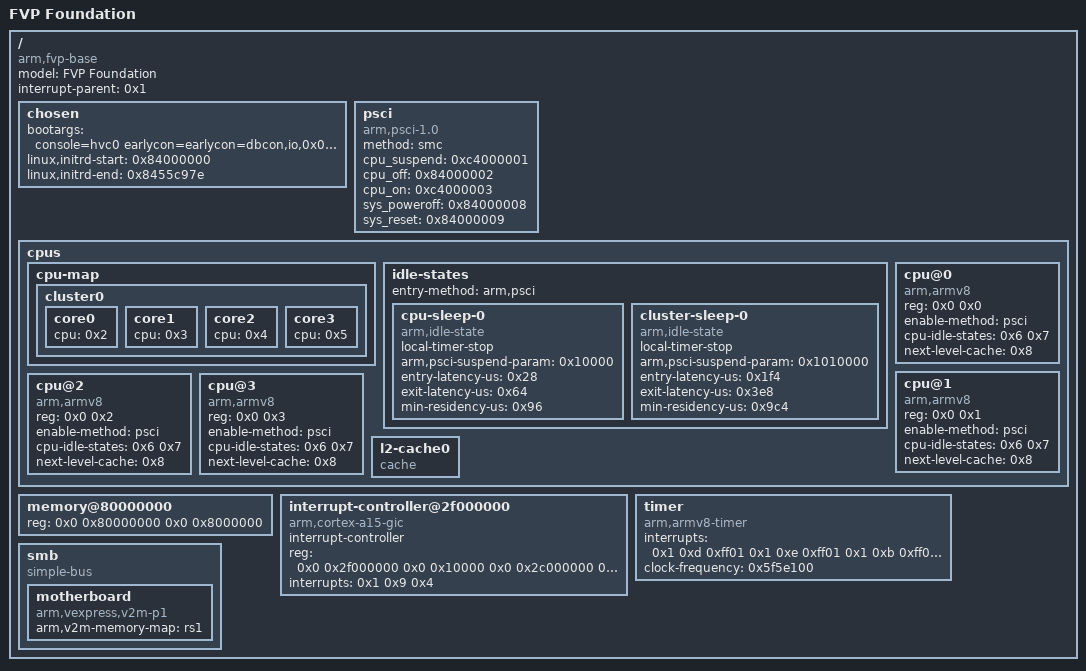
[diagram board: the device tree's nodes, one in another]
/dts-v1/;

/ {
	model = "FVP Foundation";
	compatible = "arm,fvp-base", "arm,vexpress";
	interrupt-parent = <0x1>;
	#address-cells = <0x2>;
	#size-cells = <0x2>;

	chosen {
		bootargs = "console=hvc0 earlycon=earlycon=dbcon,io,0x0 loglevel=8 consolelog=9";
		linux,initrd-start = <0x84000000>;
		linux,initrd-end = <0x8455c97e>;
	};

	psci {
		compatible = "arm,psci-1.0", "arm,psci-0.2", "arm,psci";
		method = "smc";
		cpu_suspend = <0xc4000001>;
		cpu_off = <0x84000002>;
		cpu_on = <0xc4000003>;
		sys_poweroff = <0x84000008>;
		sys_reset = <0x84000009>;
	};

	cpus {
		#address-cells = <0x2>;
		#size-cells = <0x0>;

		cpu-map {

			cluster0 {

				core0 {
					cpu = <0x2>;
				};

				core1 {
					cpu = <0x3>;
				};

				core2 {
					cpu = <0x4>;
				};

				core3 {
					cpu = <0x5>;
				};
			};
		};

		idle-states {
			entry-method = "arm,psci";

			cpu-sleep-0 {
				compatible = "arm,idle-state";
				local-timer-stop;
				arm,psci-suspend-param = <0x10000>;
				entry-latency-us = <0x28>;
				exit-latency-us = <0x64>;
				min-residency-us = <0x96>;
				linux,phandle = <0x6>;
				phandle = <0x6>;
			};

			cluster-sleep-0 {
				compatible = "arm,idle-state";
				local-timer-stop;
				arm,psci-suspend-param = <0x1010000>;
				entry-latency-us = <0x1f4>;
				exit-latency-us = <0x3e8>;
				min-residency-us = <0x9c4>;
				linux,phandle = <0x7>;
				phandle = <0x7>;
			};
		};

		cpu@0 {
			device_type = "cpu";
			compatible = "arm,armv8";
			reg = <0x0 0x0>;
			enable-method = "psci";
			cpu-idle-states = <0x6 0x7>;
			next-level-cache = <0x8>;
			linux,phandle = <0x2>;
			phandle = <0x2>;
		};

		cpu@1 {
			device_type = "cpu";
			compatible = "arm,armv8";
			reg = <0x0 0x1>;
			enable-method = "psci";
			cpu-idle-states = <0x6 0x7>;
			next-level-cache = <0x8>;
			linux,phandle = <0x3>;
			phandle = <0x3>;
		};

		cpu@2 {
			device_type = "cpu";
			compatible = "arm,armv8";
			reg = <0x0 0x2>;
			enable-method = "psci";
			cpu-idle-states = <0x6 0x7>;
			next-level-cache = <0x8>;
			linux,phandle = <0x4>;
			phandle = <0x4>;
		};

		cpu@3 {
			device_type = "cpu";
			compatible = "arm,armv8";
			reg = <0x0 0x3>;
			enable-method = "psci";
			cpu-idle-states = <0x6 0x7>;
			next-level-cache = <0x8>;
			linux,phandle = <0x5>;
			phandle = <0x5>;
		};

		l2-cache0 {
			compatible = "cache";
			linux,phandle = <0x8>;
			phandle = <0x8>;
		};
	};

	memory@80000000 {
		device_type = "memory";
		reg = <0x0 0x80000000 0x0 0x8000000>;
	};

	interrupt-controller@2f000000 {
		compatible = "arm,cortex-a15-gic", "arm,cortex-a9-gic";
		#interrupt-cells = <0x3>;
		#address-cells = <0x2>;
		#size-cells = <0x2>;
		interrupt-controller;
		reg = <0x0 0x2f000000 0x0 0x10000 0x0 0x2c000000 0x0 0x2000 0x0 0x2c010000 0x0 0x2000 0x0 0x2c02f000 0x0 0x2000>;
		interrupts = <0x1 0x9 0x4>;
		linux,phandle = <0x1>;
		phandle = <0x1>;
	};

	timer {
		compatible = "arm,armv8-timer";
		interrupts = <0x1 0xd 0xff01 0x1 0xe 0xff01 0x1 0xb 0xff01 0x1 0xa 0xff01>;
		clock-frequency = <0x5f5e100>;
	};

	smb {
		compatible = "simple-bus";
		#address-cells = <0x2>;
		#size-cells = <0x1>;
		ranges = <0x0 0x0 0x0 0x8000000 0x4000000 0x1 0x0 0x0 0x14000000 0x4000000 0x2 0x0 0x0 0x18000000 0x4000000 0x3 0x0 0x0 0x1c000000 0x4000000 0x4 0x0 0x0 0xc000000 0x4000000 0x5 0x0 0x0 0x10000000 0x4000000>;

		motherboard {
			arm,v2m-memory-map = "rs1";
			compatible = "arm,vexpress,v2m-p1", "simple-bus";
			#address-cells = <0x2>;
			#size-cells = <0x1>;
			ranges;
		};
	};
};
